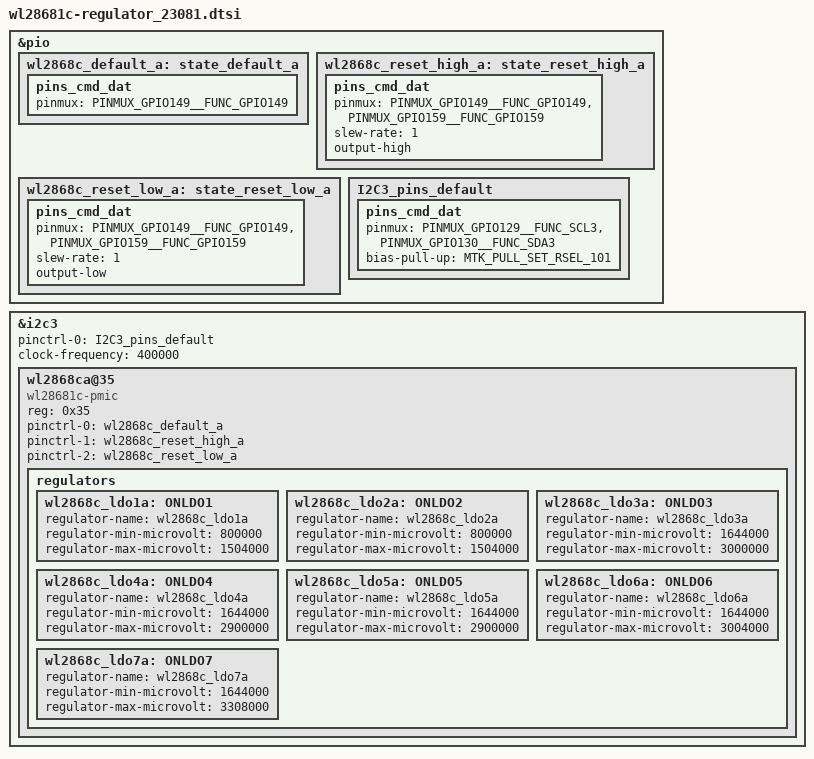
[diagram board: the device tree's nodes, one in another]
// SPDX-License-Identifier: GPL-2.0
/*
 * Copyright (C) 2021 MediaTek Inc.
 */

&pio {
	wl2868c_default_a: state_default_a {
		pins_cmd_dat {
			pinmux = <PINMUX_GPIO149__FUNC_GPIO149>;
		};
	};
	wl2868c_reset_high_a: state_reset_high_a {
		pins_cmd_dat {
			pinmux = <PINMUX_GPIO149__FUNC_GPIO149>,
					<PINMUX_GPIO159__FUNC_GPIO159>;
			slew-rate = <1>;
			output-high;
		};
	};
	wl2868c_reset_low_a: state_reset_low_a {
		pins_cmd_dat {
			pinmux = <PINMUX_GPIO149__FUNC_GPIO149>,
					<PINMUX_GPIO159__FUNC_GPIO159>;
			slew-rate = <1>;
			output-low;
		};
	};

	I2C3_pins_default: I2C3_pins_default {
		pins_cmd_dat {
			pinmux = <PINMUX_GPIO129__FUNC_SCL3>,
				 <PINMUX_GPIO130__FUNC_SDA3>;
			bias-pull-up = <MTK_PULL_SET_RSEL_101>;
		};
	};

};

&i2c3 {
	pinctrl-names = "default";
	pinctrl-0 = <&I2C3_pins_default>;
	status = "okay";

	clock-frequency = <400000>;
	wl2868ca@35 {
		compatible = "wl28681c-pmic";
		reg = <0x35>;
		pinctrl-names = "default", "reset_high", "reset_low";
		pinctrl-0 = <&wl2868c_default_a>;
		pinctrl-1 = <&wl2868c_reset_high_a>;
		pinctrl-2 = <&wl2868c_reset_low_a>;
		regulators {
			wl2868c_ldo1a:ONLDO1 {
				regulator-name = "wl2868c_ldo1a";
				regulator-min-microvolt = <800000>;
				regulator-max-microvolt = <1504000>;
			};
			//dvdd 1.1
			wl2868c_ldo2a:ONLDO2 {
				regulator-name = "wl2868c_ldo2a";
				regulator-min-microvolt = <800000>;
				regulator-max-microvolt = <1504000>;
			};
			//front avdd 2.9
			wl2868c_ldo3a:ONLDO3 {
				regulator-name = "wl2868c_ldo3a";
				regulator-min-microvolt = <1644000>;
				regulator-max-microvolt = <3000000>;
			};
			//avdd 2.8
			wl2868c_ldo4a:ONLDO4 {
				regulator-name = "wl2868c_ldo4a";
				regulator-min-microvolt = <1644000>;
				regulator-max-microvolt = <2900000>;
			};
			//avdd 1.8
			wl2868c_ldo5a:ONLDO5 {
				regulator-name = "wl2868c_ldo5a";
				regulator-min-microvolt = <1644000>;
				regulator-max-microvolt = <2900000>;
			};
			//iovdd 1.8
			wl2868c_ldo6a:ONLDO6 {
				regulator-name = "wl2868c_ldo6a";
				regulator-min-microvolt = <1644000>;
				regulator-max-microvolt = <3004000>;
			};
			//tp 3.2
			wl2868c_ldo7a:ONLDO7 {
				regulator-name = "wl2868c_ldo7a";
				regulator-min-microvolt = <1644000>;
				regulator-max-microvolt = <3308000>;
			};
		};
	};
};
